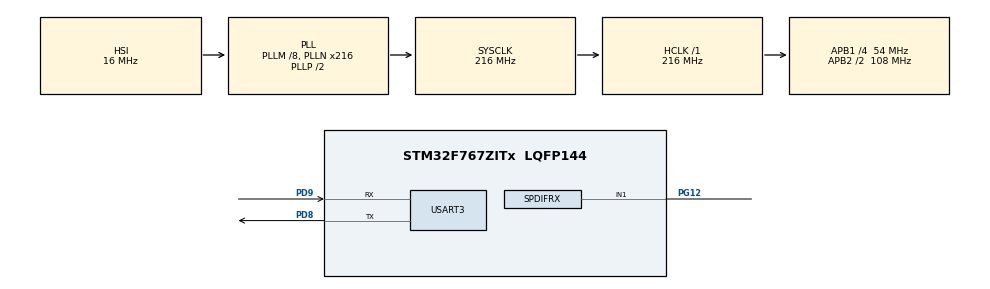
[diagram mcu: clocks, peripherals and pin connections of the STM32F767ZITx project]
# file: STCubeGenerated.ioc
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Dma.Request0=SPDIF_RX_DT
Dma.SPDIF_RX_DT.0.Direction=DMA_PERIPH_TO_MEMORY
Dma.SPDIF_RX_DT.0.FIFOMode=DMA_FIFOMODE_DISABLE
Dma.SPDIF_RX_DT.0.Instance=DMA1_Stream1
Dma.SPDIF_RX_DT.0.MemDataAlignment=DMA_MDATAALIGN_WORD
Dma.SPDIF_RX_DT.0.MemInc=DMA_MINC_ENABLE
Dma.SPDIF_RX_DT.0.Mode=DMA_CIRCULAR
Dma.SPDIF_RX_DT.0.PeriphDataAlignment=DMA_PDATAALIGN_WORD
Dma.SPDIF_RX_DT.0.PeriphInc=DMA_PINC_DISABLE
Dma.SPDIF_RX_DT.0.Priority=DMA_PRIORITY_LOW
Mcu.Family=STM32F7
Mcu.Name=STM32F767ZITx
Mcu.Package=LQFP144
NVIC.DMA1_Stream1_IRQn=true\:0\:0\:false\:false\:true\:false\:true
NVIC.PriorityGroup=NVIC_PRIORITYGROUP_4
NVIC.SPDIF_RX_IRQn=true\:0\:0\:false\:false\:true\:true\:true
PD8.Mode=Asynchronous
PD8.Signal=USART3_TX
PD9.Mode=Asynchronous
PD9.Signal=USART3_RX
PG12.Mode=IN1
PG12.Signal=SPDIFRX_IN1
PH0/OSC_IN.Mode=HSE-External-Clock-Source
PH0/OSC_IN.Signal=RCC_OSC_IN
PH1/OSC_OUT.Mode=HSE-External-Clock-Source
PH1/OSC_OUT.Signal=RCC_OSC_OUT
ProjectManager.HeapSize=0x200
ProjectManager.StackSize=0x400
ProjectManager.TargetToolchain=MDK-ARM V5
RCC.AHBFreq_Value=216000000
RCC.APB1CLKDivider=RCC_HCLK_DIV4
RCC.APB1Freq_Value=54000000
RCC.APB1TimFreq_Value=108000000
RCC.APB2CLKDivider=RCC_HCLK_DIV2
RCC.APB2Freq_Value=108000000
RCC.APB2TimFreq_Value=216000000
RCC.CortexFreq_Value=216000000
RCC.HCLKFreq_Value=216000000
RCC.HSE_VALUE=8000000
RCC.HSI_VALUE=16000000
RCC.LSE_VALUE=32768
RCC.PLLM=8
RCC.PLLN=216
RCC.SYSCLKFreq_VALUE=216000000
RCC.SYSCLKSource=RCC_SYSCLKSOURCE_PLLCLK
RCC.USBFreq_Value=216000000
RCC.VCOOutputFreq_Value=432000000
SPDIFRX.ChannelStatusMask=SPDIFRX_CHANNELSTATUS_OFF
SPDIFRX.DataFormat=SPDIFRX_DATAFORMAT_MSB
SPDIFRX.PreambleTypeMask=SPDIFRX_PREAMBLETYPEMASK_ON
SPDIFRX.Retries=SPDIFRX_MAXRETRIES_15
USART3.VirtualMode-Asynchronous=VM_ASYNC
board=custom

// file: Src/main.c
/* USER CODE BEGIN Header */
/**
  ******************************************************************************
  * @file           : main.c
  * @brief          : Main program body
  ******************************************************************************
  * @attention
  *
  * <h2><center>&copy; Copyright (c) 2021 STMicroelectronics.
  * All rights reserved.</center></h2>
  *
  * This software component is licensed by ST under BSD 3-Clause license,
  * the "License"; You may not use this file except in compliance with the
  * License. You may obtain a copy of the License at:
  *                        opensource.org/licenses/BSD-3-Clause
  *
  ******************************************************************************
  */
/* USER CODE END Header */
#include "main.h"

/* USER CODE BEGIN Includes */
#include "stdbool.h"
#include "arm_math.h"
#include "dsp.h"

/* USER CODE END Includes */

#define FFT_LENGTH	2048

SPDIFRX_HandleTypeDef hspdif;
DMA_HandleTypeDef hdma_spdif_rx_dt;

UART_HandleTypeDef huart3;

/* USER CODE BEGIN PV */
int32_t samples[FFT_LENGTH];
float32_t time_domain[FFT_LENGTH];
float32_t freq_domain[FFT_LENGTH];

volatile bool fft_complete_flag = false;

/* USER CODE END PV */

void SystemClock_Config(void);
static void MX_GPIO_Init(void);
static void MX_DMA_Init(void);
static void MX_SPDIFRX_Init(void);
static void MX_USART3_UART_Init(void);

int main(void)
{

  /* MCU Configuration--------------------------------------------------------*/

  /* Reset of all peripherals, Initializes the Flash interface and the Systick. */
  HAL_Init();

  /* Configure the system clock */
  SystemClock_Config();

  /* Initialize all configured peripherals */
  MX_GPIO_Init();
  MX_DMA_Init();
  MX_SPDIFRX_Init();
  MX_USART3_UART_Init();
  /* USER CODE BEGIN 2 */

	// Init fft
	dsp_fft_init(FFT_LENGTH);

	// Start SPDIFRX in DMA mode
	HAL_SPDIFRX_ReceiveDataFlow_DMA(&hspdif, (uint32_t*)samples, FFT_LENGTH);

  /* USER CODE END 2 */

  /* Infinite loop */
  /* USER CODE BEGIN WHILE */
  while (1)
  {
		// wait for dma and fft to complete and reset the flag
		while(fft_complete_flag == false);
		fft_complete_flag = false;

		// print spectrum out
		HAL_UART_Transmit(&huart3, freq_domain, FFT_LENGTH / 2 * sizeof(float32_t), UINT32_MAX);

    /* USER CODE END WHILE */

  }
}

void SystemClock_Config(void)
{
  RCC_OscInitTypeDef RCC_OscInitStruct = {0};
  RCC_ClkInitTypeDef RCC_ClkInitStruct = {0};
  RCC_PeriphCLKInitTypeDef PeriphClkInitStruct = {0};

  /** Configure the main internal regulator output voltage
  */
  __HAL_RCC_PWR_CLK_ENABLE();
  __HAL_PWR_VOLTAGESCALING_CONFIG(PWR_REGULATOR_VOLTAGE_SCALE1);
  /** Initializes the RCC Oscillators according to the specified parameters
  * in the RCC_OscInitTypeDef structure.
  */
  RCC_OscInitStruct.OscillatorType = RCC_OSCILLATORTYPE_HSI;
  RCC_OscInitStruct.HSIState = RCC_HSI_ON;
  RCC_OscInitStruct.HSICalibrationValue = RCC_HSICALIBRATION_DEFAULT;
  RCC_OscInitStruct.PLL.PLLState = RCC_PLL_ON;
  RCC_OscInitStruct.PLL.PLLSource = RCC_PLLSOURCE_HSI;
  RCC_OscInitStruct.PLL.PLLM = 8;
  RCC_OscInitStruct.PLL.PLLN = 216;
  RCC_OscInitStruct.PLL.PLLP = RCC_PLLP_DIV2;
  RCC_OscInitStruct.PLL.PLLQ = 2;
  if (HAL_RCC_OscConfig(&RCC_OscInitStruct) != HAL_OK)
  {
    Error_Handler();
  }
  /** Activate the Over-Drive mode
  */
  if (HAL_PWREx_EnableOverDrive() != HAL_OK)
  {
    Error_Handler();
  }
  /** Initializes the CPU, AHB and APB buses clocks
  */
  RCC_ClkInitStruct.ClockType = RCC_CLOCKTYPE_HCLK|RCC_CLOCKTYPE_SYSCLK
                              |RCC_CLOCKTYPE_PCLK1|RCC_CLOCKTYPE_PCLK2;
  RCC_ClkInitStruct.SYSCLKSource = RCC_SYSCLKSOURCE_PLLCLK;
  RCC_ClkInitStruct.AHBCLKDivider = RCC_SYSCLK_DIV1;
  RCC_ClkInitStruct.APB1CLKDivider = RCC_HCLK_DIV4;
  RCC_ClkInitStruct.APB2CLKDivider = RCC_HCLK_DIV2;

  if (HAL_RCC_ClockConfig(&RCC_ClkInitStruct, FLASH_LATENCY_7) != HAL_OK)
  {
    Error_Handler();
  }
  PeriphClkInitStruct.PeriphClockSelection = RCC_PERIPHCLK_SPDIFRX|RCC_PERIPHCLK_USART3;
  PeriphClkInitStruct.PLLI2S.PLLI2SN = 192;
  PeriphClkInitStruct.PLLI2S.PLLI2SP = RCC_PLLP_DIV2;
  PeriphClkInitStruct.PLLI2S.PLLI2SR = 2;
  PeriphClkInitStruct.PLLI2S.PLLI2SQ = 2;
  PeriphClkInitStruct.PLLI2SDivQ = 1;
  PeriphClkInitStruct.Usart3ClockSelection = RCC_USART3CLKSOURCE_PCLK1;
  if (HAL_RCCEx_PeriphCLKConfig(&PeriphClkInitStruct) != HAL_OK)
  {
    Error_Handler();
  }
}

static void MX_SPDIFRX_Init(void)
{

  hspdif.Instance = SPDIFRX;
  hspdif.Init.InputSelection = SPDIFRX_INPUT_IN1;
  hspdif.Init.Retries = SPDIFRX_MAXRETRIES_15;
  hspdif.Init.WaitForActivity = SPDIFRX_WAITFORACTIVITY_OFF;
  hspdif.Init.ChannelSelection = SPDIFRX_CHANNEL_A;
  hspdif.Init.DataFormat = SPDIFRX_DATAFORMAT_MSB;
  hspdif.Init.StereoMode = SPDIFRX_STEREOMODE_DISABLE;
  hspdif.Init.PreambleTypeMask = SPDIFRX_PREAMBLETYPEMASK_ON;
  hspdif.Init.ChannelStatusMask = SPDIFRX_CHANNELSTATUS_OFF;
  hspdif.Init.ValidityBitMask = SPDIFRX_VALIDITYMASK_OFF;
  hspdif.Init.ParityErrorMask = SPDIFRX_PARITYERRORMASK_OFF;
  if (HAL_SPDIFRX_Init(&hspdif) != HAL_OK)
  {
    Error_Handler();
  }

}

static void MX_USART3_UART_Init(void)
{

  huart3.Instance = USART3;
  huart3.Init.BaudRate = 115200;
  huart3.Init.WordLength = UART_WORDLENGTH_8B;
  huart3.Init.StopBits = UART_STOPBITS_1;
  huart3.Init.Parity = UART_PARITY_NONE;
  huart3.Init.Mode = UART_MODE_TX_RX;
  huart3.Init.HwFlowCtl = UART_HWCONTROL_NONE;
  huart3.Init.OverSampling = UART_OVERSAMPLING_16;
  huart3.Init.OneBitSampling = UART_ONE_BIT_SAMPLE_DISABLE;
  huart3.AdvancedInit.AdvFeatureInit = UART_ADVFEATURE_NO_INIT;
  if (HAL_UART_Init(&huart3) != HAL_OK)
  {
    Error_Handler();
  }

}

static void MX_DMA_Init(void)
{

  /* DMA controller clock enable */
  __HAL_RCC_DMA1_CLK_ENABLE();

  /* DMA interrupt init */
  /* DMA1_Stream1_IRQn interrupt configuration */
  HAL_NVIC_SetPriority(DMA1_Stream1_IRQn, 0, 0);
  HAL_NVIC_EnableIRQ(DMA1_Stream1_IRQn);

}

static void MX_GPIO_Init(void)
{

  /* GPIO Ports Clock Enable */
  __HAL_RCC_GPIOH_CLK_ENABLE();
  __HAL_RCC_GPIOD_CLK_ENABLE();
  __HAL_RCC_GPIOG_CLK_ENABLE();

}

/* USER CODE BEGIN 4 */

/**
  * @brief  IO character send
  * @param  ch: character to send
  * @retval ch
  */
int stdout_putchar (int ch) {
	if (UART_WaitOnFlagUntilTimeout(&huart3, UART_FLAG_TXE, RESET, HAL_GetTick(), 1000UL) == HAL_OK) {
		huart3.Instance->TDR = (uint8_t)(ch & 0xFFU);
	}

	return ch;
}

/**
  * @brief  IO character receive
  * @retval ch
  */
int stdin_getchar (void) {
	if (UART_WaitOnFlagUntilTimeout(&huart3, UART_FLAG_RXNE, RESET, HAL_GetTick(), UINT32_MAX) == HAL_OK) {
		char inChar = huart3.Instance->RDR & (uint8_t)0xFF;
		stdout_putchar(inChar);
		return inChar;
  }

	return '0';
}

void HAL_SPDIFRX_RxCpltCallback(SPDIFRX_HandleTypeDef *hspdif)
{
	// Convert raw spdif data to floats
	dsp_int2float(samples, time_domain, FFT_LENGTH);

	// Resume DMA
	HAL_SPDIFRX_ReceiveDataFlow_DMA(&hspdif, (uint32_t*)samples, FFT_LENGTH);

	// apply hamming window
	dsp_hamming(time_domain, FFT_LENGTH);

	// performm fft
	dsp_fft(time_domain, freq_domain);

	// set fft complete flag
	fft_complete_flag = true;
}

void HAL_SPDIFRX_ErrorCallback(SPDIFRX_HandleTypeDef *hspdif)
{
  printf("S/PDIFF Error callback fired! (Error code %d)\n", hspdif->ErrorCode);
}

/* USER CODE END 4 */

void Error_Handler(void)
{
  __disable_irq();
  while (1)
  {
  }
}

/************************ (C) COPYRIGHT STMicroelectronics *****END OF FILE****/
